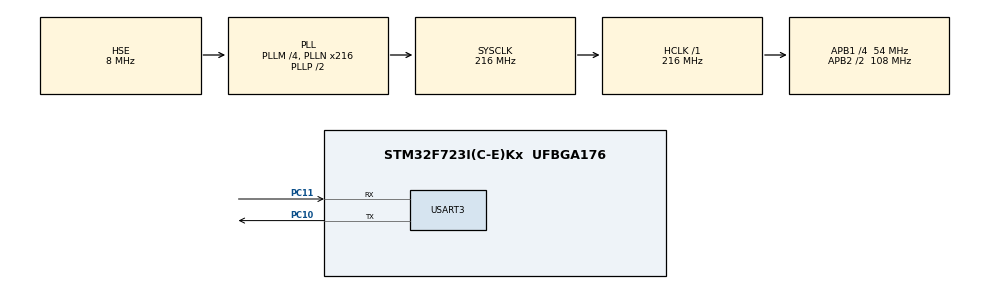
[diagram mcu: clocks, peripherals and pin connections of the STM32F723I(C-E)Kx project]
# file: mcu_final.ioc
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CORTEX_M7.CPU_DCache=Enabled
CORTEX_M7.CPU_ICache=Enabled
CORTEX_M7.default_mode_Activation=1
Mcu.Family=STM32F7
Mcu.Name=STM32F723I(C-E)Kx
Mcu.Package=UFBGA176
NVIC.PriorityGroup=NVIC_PRIORITYGROUP_4
NVIC.USART3_IRQn=true\:0\:0\:false\:false\:true\:true\:true\:true
PA13.Mode=Serial_Wire
PA13.Signal=SYS_JTMS-SWDIO
PA14.Mode=Serial_Wire
PA14.Signal=SYS_JTCK-SWCLK
PC10.Mode=Asynchronous
PC10.Signal=USART3_TX
PC11.Mode=Asynchronous
PC11.Signal=USART3_RX
PH0-OSC_IN.Mode=HSE-External-Clock-Source
PH0-OSC_IN.Signal=RCC_OSC_IN
PH1-OSC_OUT.Mode=HSE-External-Clock-Source
PH1-OSC_OUT.Signal=RCC_OSC_OUT
ProjectManager.HeapSize=0x800
ProjectManager.StackSize=0x800
ProjectManager.TargetToolchain=STM32CubeIDE
RCC.AHBFreq_Value=216000000
RCC.APB1CLKDivider=RCC_HCLK_DIV4
RCC.APB1Freq_Value=54000000
RCC.APB1TimFreq_Value=108000000
RCC.APB2CLKDivider=RCC_HCLK_DIV2
RCC.APB2Freq_Value=108000000
RCC.APB2TimFreq_Value=216000000
RCC.CortexFreq_Value=216000000
RCC.HCLKFreq_Value=216000000
RCC.HSE_VALUE=8000000
RCC.HSI_VALUE=16000000
RCC.LSE_VALUE=32768
RCC.PLLM=4
RCC.PLLMUL=RCC_PLL_MUL9
RCC.PLLN=216
RCC.PLLP=2
RCC.PLLQ=9
RCC.PLLSourceVirtual=RCC_PLLSOURCE_HSE
RCC.PRESCALERUSB=RCC_USBCLKSOURCE_PLL_DIV1_5
RCC.SYSCLKFreq_VALUE=216000000
RCC.SYSCLKSource=RCC_SYSCLKSOURCE_PLLCLK
RCC.SYSCLKSourceVirtual=RCC_SYSCLKSOURCE_PLLCLK
RCC.USBFreq_Value=48000000
RCC.VCOOutputFreq_Value=432000000
STMicroelectronics.X-CUBE-AI.10.0.0.ActivationBufferSizeList=0
STMicroelectronics.X-CUBE-AI.10.0.0.ActivationBuffers=NULL
STMicroelectronics.X-CUBE-AI.10.0.0.ApplicationCcDeviceJjApplication=Validation
STMicroelectronics.X-CUBE-AI.10.0.0.HeapSize=0x800
STMicroelectronics.X-CUBE-AI.10.0.0.LatestDirectoryUsed-b438e4eb7bbac5525da7c3b94d2324cdfaf982c64f1a84ee4064e5b1b8cd4562=J\:\\Joel\\Project
STMicroelectronics.X-CUBE-AI.10.0.0.MaximumNumberOfInputLayer=1
STMicroelectronics.X-CUBE-AI.10.0.0.MaximumNumberOfOutputLayer=1
STMicroelectronics.X-CUBE-AI.10.0.0.ModelHashList=0a7544cda9b2d20283840dcf1819ee945d4d90cc6c1f28cc7e039bdf9a0dab03
STMicroelectronics.X-CUBE-AI.10.0.0.ModelName-0a7544cda9b2d20283840dcf1819ee945d4d90cc6c1f28cc7e039bdf9a0dab03=network
STMicroelectronics.X-CUBE-AI.10.0.0.ModelNameList=network
STMicroelectronics.X-CUBE-AI.10.0.0.ModelStructureFile-b438e4eb7bbac5525da7c3b94d2324cdfaf982c64f1a84ee4064e5b1b8cd4562=J\:\\Joel\\Project\\seizure_detection_model.tflite
STMicroelectronics.X-CUBE-AI.10.0.0.ModelType-b438e4eb7bbac5525da7c3b94d2324cdfaf982c64f1a84ee4064e5b1b8cd4562=TFLite Micro runtime
STMicroelectronics.X-CUBE-AI.10.0.0.ReadyForCodeGeneration=false
STMicroelectronics.X-CUBE-AI.10.0.0.StackSize=0x800
STMicroelectronics.X-CUBE-AI.10.0.0.WorkingBufferStartAddrList=0xFFFFFFFF
STMicroelectronics.X-CUBE-AI.10.0.0.XAaCUBEAaAICcArtificialOoIntelligenceJjCore=true
STMicroelectronics.X-CUBE-AI.10.0.0.copyWeightToRam=false
STMicroelectronics.X-CUBE-AI.10.0.0.customLayerConfigEnabled=false
STMicroelectronics.X-CUBE-AI.10.0.0.noOnnxIoTranspose=false
STMicroelectronics.X-CUBE-AI.10.0.0.useInputAllocation=true
STMicroelectronics.X-CUBE-AI.10.0.0.useOutputAllocation=true
USART3.VirtualMode-Asynchronous=VM_ASYNC
VP_STMicroelectronics.X-CUBE-AI_VS_ArtificialOoIntelligenceJjXAaCUBEAaAI_10.0.0.Mode=ArtificialOoIntelligenceJjXAaCUBEAaAI
VP_STMicroelectronics.X-CUBE-AI_VS_DeviceJjApplication_10.0.0.Mode=DeviceJjApplication
board=custom

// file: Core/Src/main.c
/* USER CODE BEGIN Header */
/**
  ******************************************************************************
  * @file           : main.c
  * @brief          : Main program body
  ******************************************************************************
  */
/* USER CODE END Header */
#include <stdio.h>
#include <sys/stat.h>  // Include this for struct stat
#include "app_x-cube-ai.h"  // Your other includes
#include "main.h"

UART_HandleTypeDef huart3;

void SystemClock_Config(void);
static void MPU_Config(void);
static void MX_GPIO_Init(void);
static void MX_USART3_UART_Init(void);

/* USER CODE BEGIN 0 */

// Implement the required functions for printf and I/O operations
int _write(int file, char *ptr, int len) {
    int i;
    for (i = 0; i < len; i++) {
        HAL_UART_Transmit(&huart3, (uint8_t*)ptr, len, HAL_MAX_DELAY);  // For STM32, use UART to send characters to the terminal
    }
    return len;
}

int _read(int file, char *ptr, int len) {
    // Implement as necessary, return 0 if not required
    return 0;
}

int _close(int file) {
    // Close function implementation (if needed)
    return -1;
}

int _lseek(int file, int ptr, int dir) {
    // lseek implementation (if needed)
    return 0;
}

int _fstat(int file, struct stat *st) {
    // fstat implementation (if needed)
    return 0;
}

int _isatty(int file) {
    // isatty implementation (if needed)
    return 1;
}

// Your main function where you use printf
int main(void) {
    /* USER CODE BEGIN 1 */
    /* MPU Configuration */
    MPU_Config();

    /* Enable the CPU Cache */
    SCB_EnableICache();
    SCB_EnableDCache();

    /* MCU Configuration */
    HAL_Init();  // Initialize the HAL Library

    /* Configure the system clock */
    SystemClock_Config();

    /* Initialize all configured peripherals */
    MX_GPIO_Init();
    MX_USART3_UART_Init();
    MX_X_CUBE_AI_Init();  // Initialize AI module

    /* USER CODE END 1 */

    /* Infinite loop */
    while (1) {
        printf("Hello from STM32!\r\n");
        HAL_Delay(1000);  // Delay to prevent spamming

        MX_X_CUBE_AI_Process();  // AI processing loop
    }
}

/* USER CODE END 0 */

void SystemClock_Config(void)
{
  RCC_OscInitTypeDef RCC_OscInitStruct = {0};
  RCC_ClkInitTypeDef RCC_ClkInitStruct = {0};

  /* Configure the main internal regulator output voltage */
  __HAL_RCC_PWR_CLK_ENABLE();
  __HAL_PWR_VOLTAGESCALING_CONFIG(PWR_REGULATOR_VOLTAGE_SCALE1);

  /* Initializes the RCC Oscillators according to the specified parameters */
  RCC_OscInitStruct.OscillatorType = RCC_OSCILLATORTYPE_HSE;
  RCC_OscInitStruct.HSEState = RCC_HSE_BYPASS;
  RCC_OscInitStruct.PLL.PLLState = RCC_PLL_ON;
  RCC_OscInitStruct.PLL.PLLSource = RCC_PLLSOURCE_HSE;
  RCC_OscInitStruct.PLL.PLLM = 4;
  RCC_OscInitStruct.PLL.PLLN = 216;
  RCC_OscInitStruct.PLL.PLLP = 2;
  RCC_OscInitStruct.PLL.PLLQ = 9;
  if (HAL_RCC_OscConfig(&RCC_OscInitStruct) != HAL_OK)
  {
    Error_Handler();
  }

  /* Activate the Over-Drive mode */
  if (HAL_PWREx_EnableOverDrive() != HAL_OK)
  {
    Error_Handler();
  }

  /* Initializes the CPU, AHB, and APB buses clocks */
  RCC_ClkInitStruct.ClockType = RCC_CLOCKTYPE_HCLK|RCC_CLOCKTYPE_SYSCLK
                              |RCC_CLOCKTYPE_PCLK1|RCC_CLOCKTYPE_PCLK2;
  RCC_ClkInitStruct.SYSCLKSource = RCC_SYSCLKSOURCE_PLLCLK;
  RCC_ClkInitStruct.AHBCLKDivider = RCC_SYSCLK_DIV1;
  RCC_ClkInitStruct.APB1CLKDivider = RCC_HCLK_DIV4;
  RCC_ClkInitStruct.APB2CLKDivider = RCC_HCLK_DIV2;

  if (HAL_RCC_ClockConfig(&RCC_ClkInitStruct, FLASH_LATENCY_7) != HAL_OK)
  {
    Error_Handler();
  }
}

static void MX_USART3_UART_Init(void)
{
  huart3.Instance = USART3;
  huart3.Init.BaudRate = 115200;
  huart3.Init.WordLength = UART_WORDLENGTH_8B;
  huart3.Init.StopBits = UART_STOPBITS_1;
  huart3.Init.Parity = UART_PARITY_NONE;
  huart3.Init.Mode = UART_MODE_TX_RX;
  huart3.Init.HwFlowCtl = UART_HWCONTROL_NONE;
  huart3.Init.OverSampling = UART_OVERSAMPLING_16;
  huart3.Init.OneBitSampling = UART_ONE_BIT_SAMPLE_DISABLE;
  huart3.AdvancedInit.AdvFeatureInit = UART_ADVFEATURE_NO_INIT;
  if (HAL_UART_Init(&huart3) != HAL_OK)
  {
    Error_Handler();
  }
}

static void MX_GPIO_Init(void)
{
  /* GPIO Ports Clock Enable */
  __HAL_RCC_GPIOA_CLK_ENABLE();
  __HAL_RCC_GPIOC_CLK_ENABLE();
  __HAL_RCC_GPIOH_CLK_ENABLE();
}

/* MPU Configuration */
void MPU_Config(void)
{
  MPU_Region_InitTypeDef MPU_InitStruct = {0};

  /* Disables the MPU */
  HAL_MPU_Disable();

  /* Initializes and configures the Region and the memory to be protected */
  MPU_InitStruct.Enable = MPU_REGION_ENABLE;
  MPU_InitStruct.Number = MPU_REGION_NUMBER0;
  MPU_InitStruct.BaseAddress = 0x0;
  MPU_InitStruct.Size = MPU_REGION_SIZE_4GB;
  MPU_InitStruct.SubRegionDisable = 0x87;
  MPU_InitStruct.TypeExtField = MPU_TEX_LEVEL0;
  MPU_InitStruct.AccessPermission = MPU_REGION_NO_ACCESS;
  MPU_InitStruct.DisableExec = MPU_INSTRUCTION_ACCESS_DISABLE;
  MPU_InitStruct.IsShareable = MPU_ACCESS_SHAREABLE;
  MPU_InitStruct.IsCacheable = MPU_ACCESS_NOT_CACHEABLE;
  MPU_InitStruct.IsBufferable = MPU_ACCESS_NOT_BUFFERABLE;

  HAL_MPU_ConfigRegion(&MPU_InitStruct);
  /* Enables the MPU */
  HAL_MPU_Enable(MPU_PRIVILEGED_DEFAULT);
}

void Error_Handler(void)
{
  /* USER CODE BEGIN Error_Handler_Debug */
  /* User can add his own implementation to report the HAL error return state */
  __disable_irq();
  while (1)
  {
    printf("Hello from STM32!\r\n");  // Print message
    HAL_Delay(1000);                 // 1-second delay
  }
  /* USER CODE END Error_Handler_Debug */
}
